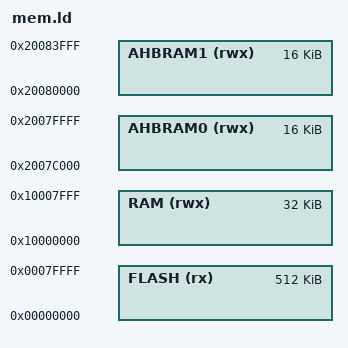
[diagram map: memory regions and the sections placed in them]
/*
 * This file is part of the µOS++ distribution.
 *   (https://github.com/micro-os-plus)
 * Copyright (c) 2014 Liviu Ionescu.
 *
 * Permission is hereby granted, free of charge, to any person
 * obtaining a copy of this software and associated documentation
 * files (the "Software"), to deal in the Software without
 * restriction, including without limitation the rights to use,
 * copy, modify, merge, publish, distribute, sublicense, and/or
 * sell copies of the Software, and to permit persons to whom
 * the Software is furnished to do so, subject to the following
 * conditions:
 *
 * The above copyright notice and this permission notice shall be
 * included in all copies or substantial portions of the Software.
 *
 * THE SOFTWARE IS PROVIDED "AS IS", WITHOUT WARRANTY OF ANY KIND,
 * EXPRESS OR IMPLIED, INCLUDING BUT NOT LIMITED TO THE WARRANTIES
 * OF MERCHANTABILITY, FITNESS FOR A PARTICULAR PURPOSE AND
 * NONINFRINGEMENT. IN NO EVENT SHALL THE AUTHORS OR COPYRIGHT
 * HOLDERS BE LIABLE FOR ANY CLAIM, DAMAGES OR OTHER LIABILITY,
 * WHETHER IN AN ACTION OF CONTRACT, TORT OR OTHERWISE, ARISING
 * FROM, OUT OF OR IN CONNECTION WITH THE SOFTWARE OR THE USE OR
 * OTHER DEALINGS IN THE SOFTWARE.
 */

/*
 * Memory Spaces Definitions.
 *
 * Need modifying for a specific board. 
 *   FLASH.ORIGIN: starting address of flash
 *   FLASH.LENGTH: length of flash
 *   RAM.ORIGIN: starting address of RAM bank 0
 *   RAM.LENGTH: length of RAM bank 0
 *
 * The values below can be addressed in further linker scripts
 * using functions like 'ORIGIN(RAM)' or 'LENGTH(RAM)'.
 */

MEMORY
{
	FLASH (rx) 	: ORIGIN = 0x00000000, LENGTH = 0x80000
	RAM (rwx) 	: ORIGIN = 0x10000000, LENGTH = 0x8000
	AHBRAM0(rwx): ORIGIN = 0x2007c000, LENGTH = 0x4000
	AHBRAM1(rwx): ORIGIN = 0x20080000, LENGTH = 0x4000
}
